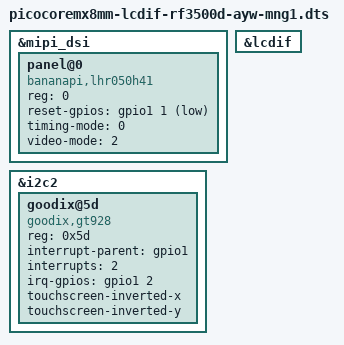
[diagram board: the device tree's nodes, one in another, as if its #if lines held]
/*
 * Copyright 2017 NXP
 *
 * This program is free software; you can redistribute it and/or
 * modify it under the terms of the GNU General Public License
 * as published by the Free Software Foundation; either version 2
 * of the License, or (at your option) any later version.
 *
 * This program is distributed in the hope that it will be useful,
 * but WITHOUT ANY WARRANTY; without even the implied warranty of
 * MERCHANTABILITY or FITNESS FOR A PARTICULAR PURPOSE.  See the
 * GNU General Public License for more details.
 */

#include "picocoremx8mm-bbdsi.dts"


&mipi_dsi {
	status = "okay";

	panel@0 {
		status = "okay";
                compatible = "bananapi,lhr050h41", "ilitek,ili9881c";
		reg = <0>;

		reset-gpios = <&gpio1 1 GPIO_ACTIVE_LOW>;
		timing-mode = <0>;
		video-mode = <2>;

	};
};

&lcdif {
	status = "okay";
};

&i2c2 {
	/* touch I2C */
	goodix@5d {
		compatible = "goodix,gt928";
		reg = <0x5d>;
#if (CONFIG_PICOCOREMX8MM_BOARD_REVISION==100)
		interrupt-parent = <&gpio1>;
		interrupts = <2 >;
		irq-gpios = <&gpio1 2 IRQ_TYPE_EDGE_FALLING>;
#else
		interrupt-parent = <&gpio4>;
		interrupts = <31 0>;
		irq-gpios = <&gpio4 31 GPIO_ACTIVE_HIGH>;
#endif
		/* reset-gpios = <&gpio1 10 GPIO_ACTIVE_LOW>; */

#ifdef CONFIG_PICOCOREMX8MM_INVERTED_XY
		touchscreen-inverted-x;
		touchscreen-inverted-y;
#endif

	};
};


